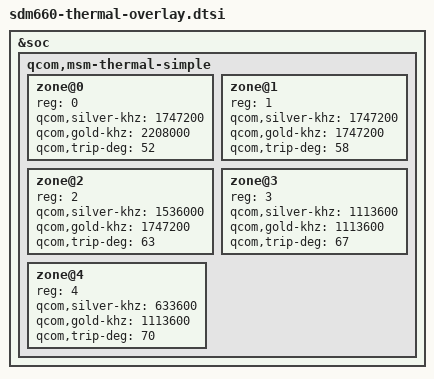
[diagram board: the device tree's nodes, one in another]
/* sdm660.dtsi X00TD specific diff */
&soc {
	qcom,msm-thermal-simple {
		zone@0 {
			reg = <0>;
			qcom,silver-khz = <1747200>;
			qcom,gold-khz = <2208000>;
			qcom,trip-deg = <52>;
		};

		zone@1 {
			reg = <1>;
			qcom,silver-khz = <1747200>;
			qcom,gold-khz = <1747200>;
			qcom,trip-deg = <58>;
		};

		zone@2 {
			reg = <2>;
			qcom,silver-khz = <1536000>;
			qcom,gold-khz = <1747200>;
			qcom,trip-deg = <63>;
		};

		zone@3 {
			reg = <3>;
			qcom,silver-khz = <1113600>;
			qcom,gold-khz = <1113600>;
			qcom,trip-deg = <67>;
		};

		zone@4 {
			reg = <4>;
			qcom,silver-khz = <633600>;
			qcom,gold-khz = <1113600>;
			qcom,trip-deg = <70>;
		};
	};
};
